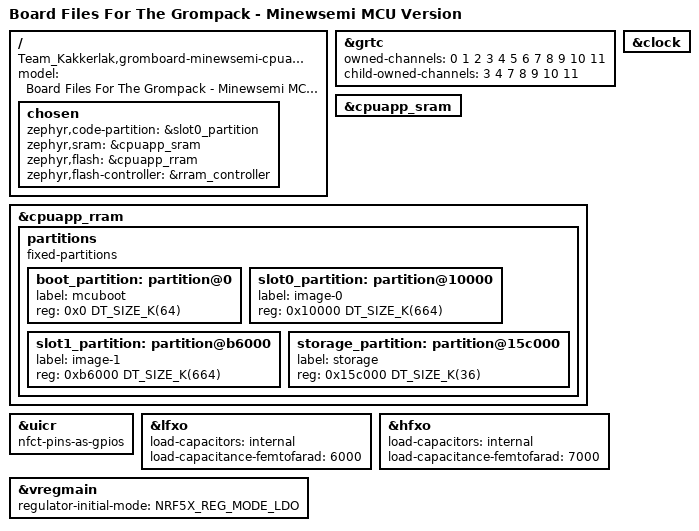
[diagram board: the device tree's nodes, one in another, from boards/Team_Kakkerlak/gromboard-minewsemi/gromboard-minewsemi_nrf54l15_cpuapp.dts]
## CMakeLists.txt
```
cmake_minimum_required(VERSION 3.20.0)
find_package(Zephyr REQUIRED HINTS $ENV{ZEPHYR_BASE})

project(grompack_firmware)

target_sources(app PRIVATE src/main.c src/timer.c src/saadc.c src/gppi.c src/ble.c)
```

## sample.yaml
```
sample:
  description: grompack firmware for ble and adc.
  name: GromPack Firmware

common:
  sysbuild: true
  build_only: true
  skip: true
  integration_platforms:
    - nrf54l15dk/nrf54l15/cpuapp
    - nrf54l15dk/nrf54l15/cpuapp/ns
  platform_allow:
    - nrf54l15dk/nrf54l15/cpuapp
    - nrf54l15dk/nrf54l15/cpuapp/ns
```

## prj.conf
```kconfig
# CONFIG_LOG=y
```

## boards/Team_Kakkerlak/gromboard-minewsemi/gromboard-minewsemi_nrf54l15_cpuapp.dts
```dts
/dts-v1/;

#include <nordic/nrf54l15_cpuapp.dtsi>

/ {
	model = "Board Files For The Grompack - Minewsemi MCU Version";
	compatible = "Team_Kakkerlak,gromboard-minewsemi-cpuapp";

	chosen {
		zephyr,code-partition = &slot0_partition;
		zephyr,sram = &cpuapp_sram;
		zephyr,flash = &cpuapp_rram;
		zephyr,flash-controller = &rram_controller;
	};

};

&grtc {
	owned-channels = <0 1 2 3 4 5 6 7 8 9 10 11>;
	/* Channels 7-11 reserved for Zero Latency IRQs, 3-4 for FLPR */
	child-owned-channels = <3 4 7 8 9 10 11>;
	status = "okay";
};

&cpuapp_sram {
	status = "okay";
};

&cpuapp_rram {
	partitions {
		compatible = "fixed-partitions";
		#address-cells = <1>;
		#size-cells = <1>;

		boot_partition: partition@0 {
			label = "mcuboot";
			reg = <0x0 DT_SIZE_K(64)>;
		};

		slot0_partition: partition@10000 {
			label = "image-0";
			reg = <0x10000 DT_SIZE_K(664)>;
		};

		slot1_partition: partition@b6000 {
			label = "image-1";
			reg = <0xb6000 DT_SIZE_K(664)>;
		};

		storage_partition: partition@15c000 {
			label = "storage";
			reg = <0x15c000 DT_SIZE_K(36)>;
		};
	};
};

&uicr {
	nfct-pins-as-gpios;
};

&clock {
	status = "okay";
};

&lfxo {
    status = "okay";
    load-capacitors = "internal";
    load-capacitance-femtofarad = <6000>;
};

&hfxo {
    status = "okay";
    load-capacitors = "internal";
    load-capacitance-femtofarad = <7000>;
};

&vregmain {
    regulator-initial-mode = <NRF5X_REG_MODE_LDO>;
};
```

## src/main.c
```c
#include <zephyr/kernel.h>

#include "peripherals.h"

LOG_MODULE_REGISTER(grompack_logger, LOG_LEVEL_DBG);

K_MSGQ_DEFINE(ble_data_queue, sizeof(struct neural_packet), 10, 4);

system_status_t status_flag = STATUS_OK;

int main(void) {
    int err;

    configure_timer();
    configure_saadc();
    configure_ppi();
    configure_ble();

    struct neural_packet tx_packet;

    while (1) {
        if (k_msgq_get(&ble_data_queue, &tx_packet, K_FOREVER) == 0) {
            if (is_laptop_subscribed) {
                err =
                    bt_nus_send(NULL, (uint8_t*)&tx_packet, sizeof(tx_packet));

                if (err && err != -EAGAIN && err != -ENOTCONN) {
                    LOG_INF("Transmission error: %d\n", err);
                }
            } else {
                LOG_INF("Laptop not subscribed, skipping transmission.\n");
            }
        }
    }
}
```

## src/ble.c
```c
#include <zephyr/bluetooth/bluetooth.h>
#include <zephyr/bluetooth/services/nus.h>
#include <zephyr/kernel.h>

#include "peripherals.h"

LOG_MODULE_DECLARE(grompack_logger, LOG_LEVEL_DBG);

#define DEVICE_NAME CONFIG_BT_DEVICE_NAME
#define DEVICE_NAME_LEN (sizeof(DEVICE_NAME) - 1)

bool is_laptop_subscribed = false;

static const struct bt_data ad[] = {
    BT_DATA_BYTES(BT_DATA_FLAGS, (BT_LE_AD_GENERAL | BT_LE_AD_NO_BREDR)),
    BT_DATA(BT_DATA_NAME_COMPLETE, DEVICE_NAME, DEVICE_NAME_LEN),
};

static const struct bt_data sd[] = {
    BT_DATA_BYTES(BT_DATA_UUID128_ALL, BT_UUID_NUS_SRV_VAL),
};

static void notif_enabled(bool enabled, void* ctx) {
    ARG_UNUSED(ctx);
    LOG_INF("Laptop Subscription: %s\n", (enabled ? "Enabled" : "Disabled"));

    is_laptop_subscribed = enabled;
}

static void received(struct bt_conn* conn, const void* data, uint16_t len,
                     void* ctx) {
    ARG_UNUSED(conn);
    ARG_UNUSED(ctx);
    LOG_INF("Command Received from Laptop: %.*s\n", len, (char*)data);
}

struct bt_nus_cb nus_listener = {
    .notif_enabled = notif_enabled,
    .received = received,
};

void configure_ble(void) {
    int err;

    err = bt_enable(NULL);
    if (err) {
        LOG_INF("BLE init failed (err %d)\n", err);
        status_flag = ERROR;
        return;
    }

    err = bt_nus_cb_register(&nus_listener, NULL);
    if (err) {
        LOG_INF("NUS callbacks failed to register (err %d)\n", err);
        status_flag = ERROR;
        return;
    }

    err = bt_le_adv_start(BT_LE_ADV_CONN_FAST_1, ad, ARRAY_SIZE(ad), sd,
                          ARRAY_SIZE(sd));
    if (err) {
        LOG_INF("Advertising failed to start (err %d)\n", err);
        status_flag = ERROR;
        return;
    }

    LOG_INF("Bluetooth initialized and advertising successfully.\n");
}
```

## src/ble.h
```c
#ifndef BLE_H
#define BLE_H

#include <stdbool.h>

//is laptop listening? 
extern bool is_laptop_subscribed;

//compact setup for advertising and connecting for main
void initialize_bluetooth(void);

#endif
```

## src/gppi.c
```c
#include <helpers/nrfx_gppi.h>
#include <nrfx_saadc.h>
#include <nrfx_timer.h>
#include <zephyr/kernel.h>

#include "peripherals.h"

void configure_ppi(void) {
    int err;

    nrfx_gppi_handle_t gppi_handle_sample;
    nrfx_gppi_handle_t gppi_handle_start;

    err = nrfx_gppi_conn_alloc(
        nrfx_timer_compare_event_address_get(&timer_instance,
                                             NRF_TIMER_CC_CHANNEL0),
        nrf_saadc_task_address_get(NRF_SAADC, NRF_SAADC_TASK_SAMPLE),
        &gppi_handle_sample);
    if (err != 0) {
        status_flag = ERROR;
        return;
    }

    err = nrfx_gppi_conn_alloc(
        nrf_saadc_event_address_get(NRF_SAADC, NRF_SAADC_EVENT_END),
        nrf_saadc_task_address_get(NRF_SAADC, NRF_SAADC_TASK_START),
        &gppi_handle_start);
    if (err != 0) {
        status_flag = ERROR;
        return;
    }

    nrfx_gppi_conn_enable(gppi_handle_sample);
    nrfx_gppi_conn_enable(gppi_handle_start);
}
```

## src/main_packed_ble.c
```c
#include <zephyr/kernel.h>
#include <zephyr/bluetooth/services/nus.h>

#include "peripherals.h" 
#include "ble.h"

K_MSGQ_DEFINE(ble_data_queue, sizeof(struct neural_packet), 10, 4);

int main(void) {
    
    int err;

    configure_timer();
    configure_saadc();
    configure_ppi();

    initialize_bluetooth();
    
    struct neural_packet tx_packet;
    
    while (1) {

        if (k_msgq_get(&ble_data_queue, &tx_packet, K_FOREVER) == 0) {
            
            if (is_laptop_subscribed) {

                err = bt_nus_send(NULL, (uint8_t *)&tx_packet, sizeof(tx_packet));

                if (err && err != -EAGAIN && err != -ENOTCONN) {
                printk("Transmission error: %d\n", err);
            }
            } else {
                printk("Laptop not subscribed, skipping transmission.\n");
            }
        }
    }
}
```

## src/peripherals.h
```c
#ifndef PERIPHERALS_H
#define PERIPHERALS_H

#include <nrfx_timer.h>
#include <zephyr/bluetooth/services/nus.h>
#include <zephyr/kernel.h>
#include <zephyr/logging/log.h>

#define PACKED_BUFFER_SIZE 240

#define SAADC_SAMPLE_INTERVAL_US 100
#define SAADC_BUFFER_SIZE 8
#define SAADC_INPUT_PIN_0 NRFX_ANALOG_EXTERNAL_AIN4
#define SAADC_INPUT_PIN_1 NRFX_ANALOG_EXTERNAL_AIN5
#define SAADC_TIMER_INST_IDX 20

extern nrfx_timer_t timer_instance;

typedef enum {
    STATUS_OK = 0,
    ERROR = BIT(1),
    // dees kunnen we extenden om wat meer error types te hebben en dan kunnen
    // we elke keer |= om die bij te houden. da werkt met Segger RTT dan kunnen
    // we op de SWD ook soort van debuggen.

    // kunnen we niet LOG_ERR() gebruiken voor debugging? want dan krijgen we
    // ook een berichtje erbij
} system_status_t;

extern system_status_t status_flag;

struct neural_packet {
    uint32_t sample_index;
    uint8_t packed_data[PACKED_BUFFER_SIZE];
} __packed;

extern struct k_msgq ble_data_queue;

#include <stdbool.h>

extern bool is_laptop_subscribed;

void configure_ble(void);
void configure_timer(void);
void configure_saadc(void);
void configure_ppi(void);

#endif
```

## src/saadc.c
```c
#include <nrfx_saadc.h>
#include <zephyr/kernel.h>

#include "peripherals.h"

// LOG_MODULE_DECLARE(grompack_logger, LOG_LEVEL_DBG);

static struct neural_packet current_tx_packet;
static uint16_t byte_fill_count = 0;
static uint32_t global_sample_counter = 0;

static nrfx_saadc_channel_t channels[2] = {
    NRFX_SAADC_DEFAULT_CHANNEL_SE(SAADC_INPUT_PIN_0, 0),
    NRFX_SAADC_DEFAULT_CHANNEL_SE(SAADC_INPUT_PIN_1, 1)};

static int16_t saadc_sample_buffer[2][SAADC_BUFFER_SIZE];

// maybe we can use this as a packet index?
// if not then i would have wanted to turn this into a bool but thats
// not the best as later on they use %2 to count the index which is a
// "safer?" atomic instruction.
static uint32_t saadc_current_buffer = 0;

static void saadc_event_handler(nrfx_saadc_evt_t const* p_event) {
    int err;
    switch (p_event->type) {
        case NRFX_SAADC_EVT_READY:
            nrfx_timer_enable(&timer_instance);
            break;

        case NRFX_SAADC_EVT_BUF_REQ:
            err = nrfx_saadc_buffer_set(
                saadc_sample_buffer[(saadc_current_buffer++) % 2],
                SAADC_BUFFER_SIZE);
            if (err != 0) {
                status_flag = ERROR;
                return;
            }
            break;

        case NRFX_SAADC_EVT_DONE: {
            int16_t* raw_data = (int16_t*)(p_event->data.done.p_buffer);

            // LOG_INF("Sample: %d", (int)raw_data[0]);

            for (int i = 0; i < (SAADC_BUFFER_SIZE / 2); i++) {
                uint16_t sample1 = (uint16_t)raw_data[i * 2] & 0x0FFF;
                uint16_t sample2 = (uint16_t)raw_data[(i * 2) + 1] & 0x0FFF;

                current_tx_packet.packed_data[byte_fill_count++] =
                    sample1 & 0xFF;
                current_tx_packet.packed_data[byte_fill_count++] =
                    ((sample1 >> 8) & 0x0F) | ((sample2 << 4) & 0xF0);
                current_tx_packet.packed_data[byte_fill_count++] =
                    (sample2 >> 4) & 0xFF;

                if (byte_fill_count >= PACKED_BUFFER_SIZE) {
                    current_tx_packet.sample_index = global_sample_counter;
                    err = k_msgq_put(&ble_data_queue, &current_tx_packet,
                                     K_NO_WAIT);
                    if (err != 0) {
                        status_flag = ERROR;
                        return;
                    }
                    byte_fill_count = 0;
                    global_sample_counter += (SAADC_BUFFER_SIZE / 2);
                }
            }
            break;
        } /* NRFX_SAADC_EVT_DONE */
        default:
            status_flag = ERROR;
            break;
    }
}

void configure_saadc(void) {
    int err;

    IRQ_CONNECT(NRFX_IRQ_NUMBER_GET(NRF_SAADC), IRQ_PRIO_LOWEST,
                nrfx_saadc_irq_handler, 0, 0);
    err = nrfx_saadc_init(NRFX_SAADC_DEFAULT_CONFIG_IRQ_PRIORITY);
    if (err != 0) {
        status_flag = ERROR;
        return;
    }

    channels[0].channel_config.gain = NRF_SAADC_GAIN1_4;
    channels[1].channel_config.gain = NRF_SAADC_GAIN1_4;
    err = nrfx_saadc_channels_config(channels, 2);
    if (err != 0) {
        status_flag = ERROR;
        return;
    }

    nrfx_saadc_adv_config_t saadc_adv_config = NRFX_SAADC_DEFAULT_ADV_CONFIG;
    err = nrfx_saadc_advanced_mode_set(BIT(0) | BIT(1),
                                       NRF_SAADC_RESOLUTION_12BIT,
                                       &saadc_adv_config, saadc_event_handler);
    if (err != 0) {
        status_flag = ERROR;
        return;
    }

    err = nrfx_saadc_buffer_set(saadc_sample_buffer[0], SAADC_BUFFER_SIZE);
    if (err != 0) {
        status_flag = ERROR;
        return;
    }

    err = nrfx_saadc_buffer_set(saadc_sample_buffer[1], SAADC_BUFFER_SIZE);
    if (err != 0) {
        status_flag = ERROR;
        return;
    }

    err = nrfx_saadc_mode_trigger();
    if (err != 0) {
        status_flag = ERROR;
        return;
    }
}
```

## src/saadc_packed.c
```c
#include <nrfx_saadc.h>
#include <zephyr/kernel.h>
#include <zephyr/logging/log.h>

#include "peripherals.h"

LOG_MODULE_REGISTER(acd_logger, LOG_LEVEL_DBG);

static struct neural_packet current_tx_packet;
static uint16_t byte_fill_count = 0;
static uint32_t global_sample_counter = 0;

static nrfx_saadc_channel_t channels[2] = {
    NRFX_SAADC_DEFAULT_CHANNEL_SE(SAADC_INPUT_PIN_0, 0),
    NRFX_SAADC_DEFAULT_CHANNEL_SE(SAADC_INPUT_PIN_1, 1)};

static int16_t saadc_sample_buffer[2][SAADC_BUFFER_SIZE];

// maybe we can use this as a packet index?
// if not then i would have wanted to turn this into a bool but thats
// not the best as later on they use %2 to count the index which is a
// "safer?" atomic instruction.
static uint32_t saadc_current_buffer = 0;

static void saadc_event_handler(nrfx_saadc_evt_t const* p_event) {
    int err;
    switch (p_event->type) {
        case NRFX_SAADC_EVT_READY:
            nrfx_timer_enable(&timer_instance);
            break;

        case NRFX_SAADC_EVT_BUF_REQ:
            err = nrfx_saadc_buffer_set(
                saadc_sample_buffer[(saadc_current_buffer++) % 2],
                SAADC_BUFFER_SIZE);
            if (err != 0) {
                status_flag = ERROR;
                return;
            }
            break;

        case NRFX_SAADC_EVT_DONE:
            int16_t *raw_data = (int16_t *)(p_event->data.done.p_buffer);

            for (int i = 0; i < (SAADC_BUFFER_SIZE / 2); i++) {
                uint16_t sample1 = (uint16_t)raw_data[i * 2] & 0x0FFF;     
                uint16_t sample2 = (uint16_t)raw_data[(i * 2) + 1] & 0x0FFF;

                current_tx_packet.packed_data[byte_fill_count++] = sample1 & 0xFF;
                current_tx_packet.packed_data[byte_fill_count++] = ((sample1 >> 8) & 0x0F) | ((sample2 << 4) & 0xF0);
                current_tx_packet.packed_data[byte_fill_count++] = (sample2 >> 4) & 0xFF;

                if (byte_fill_count >= PACKED_BUFFER_SIZE) {
                    current_tx_packet.sample_index = global_sample_counter;
                    err = k_msgq_put(&ble_data_queue, &current_tx_packet, K_NO_WAIT);
                    if (err != 0) {
                        status_flag = ERROR;
                        return;
                    }
                    byte_fill_count = 0; 
                    global_sample_counter += (SAADC_BUFFER_SIZE / 2);
                }
            }
            break;
        default:
            status_flag = ERROR;
            break;
    }
}

void configure_saadc(void) {
    int err;

    IRQ_CONNECT(NRFX_IRQ_NUMBER_GET(NRF_SAADC), IRQ_PRIO_LOWEST,
                nrfx_saadc_irq_handler, 0, 0);
    err = nrfx_saadc_init(NRFX_SAADC_DEFAULT_CONFIG_IRQ_PRIORITY);
    if (err != 0) {
        status_flag = ERROR;
        return;
    }

    channels[0].channel_config.gain = NRF_SAADC_GAIN1_4;
    channels[1].channel_config.gain = NRF_SAADC_GAIN1_4;
    err = nrfx_saadc_channels_config(channels, 2);
    if (err != 0) {
        status_flag = ERROR;
        return;
    }

    nrfx_saadc_adv_config_t saadc_adv_config = NRFX_SAADC_DEFAULT_ADV_CONFIG;
    err = nrfx_saadc_advanced_mode_set(BIT(0) | BIT(1),
                                       NRF_SAADC_RESOLUTION_12BIT,
                                       &saadc_adv_config, saadc_event_handler);
    if (err != 0) {
        status_flag = ERROR;
        return;
    }

    err = nrfx_saadc_buffer_set(saadc_sample_buffer[0], SAADC_BUFFER_SIZE);
    if (err != 0) {
        status_flag = ERROR;
        return;
    }

    err = nrfx_saadc_buffer_set(saadc_sample_buffer[1], SAADC_BUFFER_SIZE);
    if (err != 0) {
        status_flag = ERROR;
        return;
    }

    err = nrfx_saadc_mode_trigger();
    if (err != 0) {
        status_flag = ERROR;
        return;
    }
}
```
